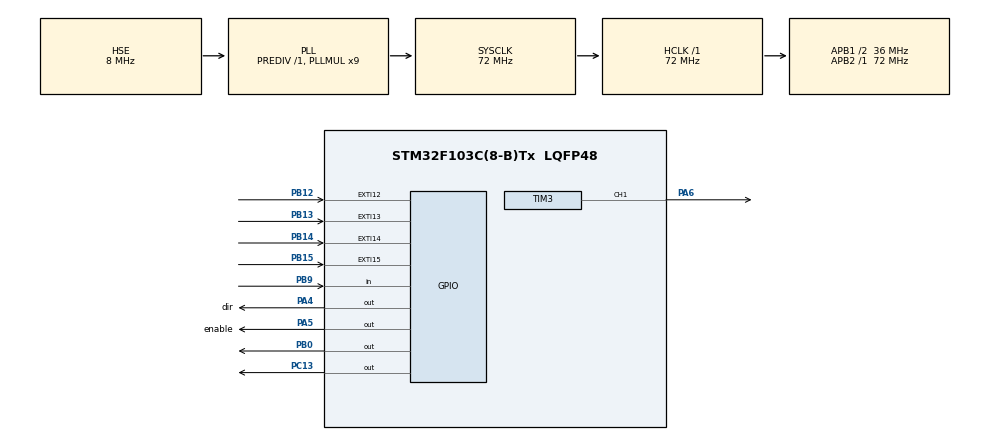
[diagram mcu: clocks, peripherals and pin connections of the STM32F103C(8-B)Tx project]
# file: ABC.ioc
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Mcu.Family=STM32F1
Mcu.Name=STM32F103C(8-B)Tx
Mcu.Package=LQFP48
NVIC.EXTI15_10_IRQn=true\:0\:0\:false\:false\:true\:true\:true\:true
NVIC.PriorityGroup=NVIC_PRIORITYGROUP_4
NVIC.RCC_IRQn=true\:0\:0\:false\:false\:true\:true\:false\:true
NVIC.TIM3_IRQn=true\:0\:0\:false\:false\:true\:true\:true\:true
PA13.Mode=Serial_Wire
PA13.Signal=SYS_JTMS-SWDIO
PA14.Mode=Serial_Wire
PA14.Signal=SYS_JTCK-SWCLK
PA4.GPIO_Label=dir
PA4.GPIO_PuPd=GPIO_PULLDOWN
PA4.Signal=GPIO_Output
PA5.GPIO_Label=enable
PA5.GPIO_PuPd=GPIO_PULLDOWN
PA5.Signal=GPIO_Output
PA6.Signal=S_TIM3_CH1
PB0.Signal=GPIO_Output
PB12.Signal=GPXTI12
PB13.GPIO_PuPd=GPIO_PULLDOWN
PB13.Signal=GPXTI13
PB14.GPIO_PuPd=GPIO_PULLDOWN
PB14.Signal=GPXTI14
PB15.GPIO_ModeDefaultEXTI=GPIO_MODE_IT_RISING
PB15.GPIO_PuPd=GPIO_PULLDOWN
PB15.Signal=GPXTI15
PB9.GPIO_PuPd=GPIO_PULLDOWN
PB9.Signal=GPIO_Input
PC13-TAMPER-RTC.Signal=GPIO_Output
PD0-OSC_IN.Mode=HSE-External-Oscillator
PD0-OSC_IN.Signal=RCC_OSC_IN
PD1-OSC_OUT.Mode=HSE-External-Oscillator
PD1-OSC_OUT.Signal=RCC_OSC_OUT
ProjectManager.HeapSize=0x200
ProjectManager.StackSize=0x400
ProjectManager.TargetToolchain=STM32CubeIDE
RCC.AHBFreq_Value=72000000
RCC.APB1CLKDivider=RCC_HCLK_DIV2
RCC.APB1Freq_Value=36000000
RCC.APB1TimFreq_Value=72000000
RCC.APB2Freq_Value=72000000
RCC.APB2TimFreq_Value=72000000
RCC.HCLKFreq_Value=72000000
RCC.PLLMUL=RCC_PLL_MUL9
RCC.PLLSourceVirtual=RCC_PLLSOURCE_HSE
RCC.SYSCLKFreq_VALUE=72000000
RCC.SYSCLKSource=RCC_SYSCLKSOURCE_PLLCLK
RCC.USBFreq_Value=72000000
SH.S_TIM3_CH1.0=TIM3_CH1,PWM Generation1 CH1
TIM3.AutoReloadPreload=TIM_AUTORELOAD_PRELOAD_ENABLE
TIM3.Channel-PWM\ Generation1\ CH1=TIM_CHANNEL_1
TIM3.Period=1000-1
TIM3.Prescaler=72-1
board=custom

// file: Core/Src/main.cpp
/* USER CODE BEGIN Header */
/**
  ******************************************************************************
  * @file           : main.c
  * @brief          : Main program body
  ******************************************************************************
  * @attention
  *
  * Copyright (c) 2023 STMicroelectronics.
  * All rights reserved.
  *
  * This software is licensed under terms that can be found in the LICENSE file
  * in the root directory of this software component.
  * If no LICENSE file comes with this software, it is provided AS-IS.
  *
  ******************************************************************************
  */
/* USER CODE END Header */
#include "main.h"
#include "../../lib/Debounce.h"
#include "../../lib/StepMotor.h"

TIM_HandleTypeDef htim3;

void SystemClock_Config(void);
static void MX_GPIO_Init(void);
static void MX_TIM3_Init(void);

uint32_t pwm = 0;
uint32_t i = 0;
uint8_t direction = 0;

volatile uint8_t flag_irq = 0;
volatile uint32_t time_irq = 0;

StepMotor* motor;

void HAL_GPIO_EXTI_Callback(uint16_t GPIO_Pin)
{
}

void HAL_TIM_PeriodElapsedCallback(TIM_HandleTypeDef *htim)		// вызывается по окончанию периода шим
{
	motor->checkMotorInCallback(htim);
}

int main(void)
{

  /* MCU Configuration--------------------------------------------------------*/

  /* Reset of all peripherals, Initializes the Flash interface and the Systick. */
  HAL_Init();

  /* Configure the system clock */
  SystemClock_Config();

  /* Initialize all configured peripherals */
  MX_GPIO_Init();
  MX_TIM3_Init();

  /* Infinite loop */
  /* USER CODE BEGIN WHILE */
  TIM_HandleTypeDef *phtim3 = &htim3;

  motor = new StepMotor(GPIOA, enable_Pin, GPIOA, dir_Pin, phtim3, TIM_CHANNEL_1);
  Debounce buttonB14(GPIOB, GPIO_PIN_14, 100);
  Debounce buttonB13(GPIOB, GPIO_PIN_13, 100);
  Debounce buttonB15(GPIOB, GPIO_PIN_15, 100);
  Debounce buttonB12(GPIOB, GPIO_PIN_12, 100);
  HAL_TIM_Base_Start_IT(&htim3);

  while (1)
  {
    /* USER CODE END WHILE */
	  if(buttonB14.CheckButton())			// red
	  {
		  	motor->setDirection(uint8_t(0));
			motor->setMaxSpeed(60000);
			motor->setMinSpeed(100);
			motor->setAccelerationStep(3000, 30000);
		  	motor->startMotion(320000);
		  	motor->setRetention(1);
	  }
	  else if(buttonB13.CheckButton())	//blue
	  {
			motor->setDirection(uint8_t(1));
			motor->setMaxSpeed(1600);
			motor->startMotion(1600);
			motor->setRetention(1);
	  }
	  else if(buttonB15.CheckButton())		// green
	  {
		  motor->setRetention(1);
	  }
	  else if(buttonB12.CheckButton())			//white
	  {
		  motor->setRetention(0);
	  }

  }
}

void SystemClock_Config(void)
{
  RCC_OscInitTypeDef RCC_OscInitStruct = {0};
  RCC_ClkInitTypeDef RCC_ClkInitStruct = {0};

  /** Initializes the RCC Oscillators according to the specified parameters
  * in the RCC_OscInitTypeDef structure.
  */
  RCC_OscInitStruct.OscillatorType = RCC_OSCILLATORTYPE_HSE;
  RCC_OscInitStruct.HSEState = RCC_HSE_ON;
  RCC_OscInitStruct.HSEPredivValue = RCC_HSE_PREDIV_DIV1;
  RCC_OscInitStruct.HSIState = RCC_HSI_ON;
  RCC_OscInitStruct.PLL.PLLState = RCC_PLL_ON;
  RCC_OscInitStruct.PLL.PLLSource = RCC_PLLSOURCE_HSE;
  RCC_OscInitStruct.PLL.PLLMUL = RCC_PLL_MUL9;
  if (HAL_RCC_OscConfig(&RCC_OscInitStruct) != HAL_OK)
  {
    Error_Handler();
  }

  /** Initializes the CPU, AHB and APB buses clocks
  */
  RCC_ClkInitStruct.ClockType = RCC_CLOCKTYPE_HCLK|RCC_CLOCKTYPE_SYSCLK
                              |RCC_CLOCKTYPE_PCLK1|RCC_CLOCKTYPE_PCLK2;
  RCC_ClkInitStruct.SYSCLKSource = RCC_SYSCLKSOURCE_PLLCLK;
  RCC_ClkInitStruct.AHBCLKDivider = RCC_SYSCLK_DIV1;
  RCC_ClkInitStruct.APB1CLKDivider = RCC_HCLK_DIV2;
  RCC_ClkInitStruct.APB2CLKDivider = RCC_HCLK_DIV1;

  if (HAL_RCC_ClockConfig(&RCC_ClkInitStruct, FLASH_LATENCY_2) != HAL_OK)
  {
    Error_Handler();
  }
}

static void MX_TIM3_Init(void)
{

  TIM_MasterConfigTypeDef sMasterConfig = {0};
  TIM_OC_InitTypeDef sConfigOC = {0};

  htim3.Instance = TIM3;
  htim3.Init.Prescaler = 73-1;
  htim3.Init.CounterMode = TIM_COUNTERMODE_UP;
  htim3.Init.Period = 1000-1;
  htim3.Init.ClockDivision = TIM_CLOCKDIVISION_DIV1;

  htim3.Init.AutoReloadPreload = TIM_AUTORELOAD_PRELOAD_ENABLE;
  if (HAL_TIM_PWM_Init(&htim3) != HAL_OK)
  {
    Error_Handler();
  }
  sMasterConfig.MasterOutputTrigger = TIM_TRGO_RESET;
  sMasterConfig.MasterSlaveMode = TIM_MASTERSLAVEMODE_DISABLE;
  if (HAL_TIMEx_MasterConfigSynchronization(&htim3, &sMasterConfig) != HAL_OK)
  {
    Error_Handler();
  }
  sConfigOC.OCMode = TIM_OCMODE_PWM1;
  sConfigOC.Pulse = 0;
  sConfigOC.OCPolarity = TIM_OCPOLARITY_HIGH;
  sConfigOC.OCFastMode = TIM_OCFAST_DISABLE;
  if (HAL_TIM_PWM_ConfigChannel(&htim3, &sConfigOC, TIM_CHANNEL_1) != HAL_OK)
  {
    Error_Handler();
  }
  HAL_TIM_MspPostInit(&htim3);

}

static void MX_GPIO_Init(void)
{
  GPIO_InitTypeDef GPIO_InitStruct = {0};

  /* GPIO Ports Clock Enable */
  __HAL_RCC_GPIOC_CLK_ENABLE();
  __HAL_RCC_GPIOD_CLK_ENABLE();
  __HAL_RCC_GPIOA_CLK_ENABLE();
  __HAL_RCC_GPIOB_CLK_ENABLE();

  /*Configure GPIO pin Output Level */
  HAL_GPIO_WritePin(GPIOC, GPIO_PIN_13, GPIO_PIN_RESET);

  /*Configure GPIO pin Output Level */
  HAL_GPIO_WritePin(GPIOA, dir_Pin|enable_Pin, GPIO_PIN_RESET);

  /*Configure GPIO pin Output Level */
  HAL_GPIO_WritePin(GPIOB, GPIO_PIN_0, GPIO_PIN_RESET);

  /*Configure GPIO pin : PC13 */
  GPIO_InitStruct.Pin = GPIO_PIN_13;
  GPIO_InitStruct.Mode = GPIO_MODE_OUTPUT_PP;
  GPIO_InitStruct.Pull = GPIO_NOPULL;
  GPIO_InitStruct.Speed = GPIO_SPEED_FREQ_LOW;
  HAL_GPIO_Init(GPIOC, &GPIO_InitStruct);

  /*Configure GPIO pins : dir_Pin enable_Pin */
  GPIO_InitStruct.Pin = dir_Pin|enable_Pin;
  GPIO_InitStruct.Mode = GPIO_MODE_OUTPUT_PP;
  GPIO_InitStruct.Pull = GPIO_PULLDOWN;
  GPIO_InitStruct.Speed = GPIO_SPEED_FREQ_LOW;
  HAL_GPIO_Init(GPIOA, &GPIO_InitStruct);

  /*Configure GPIO pin : PB0 */
  GPIO_InitStruct.Pin = GPIO_PIN_0;
  GPIO_InitStruct.Mode = GPIO_MODE_OUTPUT_PP;
  GPIO_InitStruct.Pull = GPIO_NOPULL;
  GPIO_InitStruct.Speed = GPIO_SPEED_FREQ_LOW;
  HAL_GPIO_Init(GPIOB, &GPIO_InitStruct);

  /*Configure GPIO pin : PB15 */
  GPIO_InitStruct.Pin = GPIO_PIN_12|GPIO_PIN_13|GPIO_PIN_14|GPIO_PIN_15;
  GPIO_InitStruct.Mode = GPIO_MODE_IT_RISING;
  GPIO_InitStruct.Pull = GPIO_PULLDOWN;
  HAL_GPIO_Init(GPIOB, &GPIO_InitStruct);

  /*Configure GPIO pin : PB9 */
  GPIO_InitStruct.Pin = GPIO_PIN_9;
  GPIO_InitStruct.Mode = GPIO_MODE_INPUT;
  GPIO_InitStruct.Pull = GPIO_PULLDOWN;
  HAL_GPIO_Init(GPIOB, &GPIO_InitStruct);

  /* EXTI interrupt init*/
  HAL_NVIC_SetPriority(EXTI15_10_IRQn, 0, 0);
  HAL_NVIC_EnableIRQ(EXTI15_10_IRQn);

}

void Error_Handler(void)
{
  __disable_irq();
  while (1)
  {
  }
}
